# R7KA8T2AD register map
Vendor: Renesas Electronics Corporation; Series: RA8; File version: 1.10.02
CPU: CM85 r0p2, little endian, MPU, FPU, VTOR, 4 interrupt priority bits, 96 interrupts
Registers are 32-bit, read-write, reset 0x0 unless marked. A register's access mark holds for its fields unless they carry their own. Offsets are from the block's base; [hi:lo] are bit positions; {n}, {i} and the like mark numbered series; 'fields as' and 'values as' point back to an identical list.

## I3C (part 2 of 2) — I3C Bus Interface
Base 0x4035F000
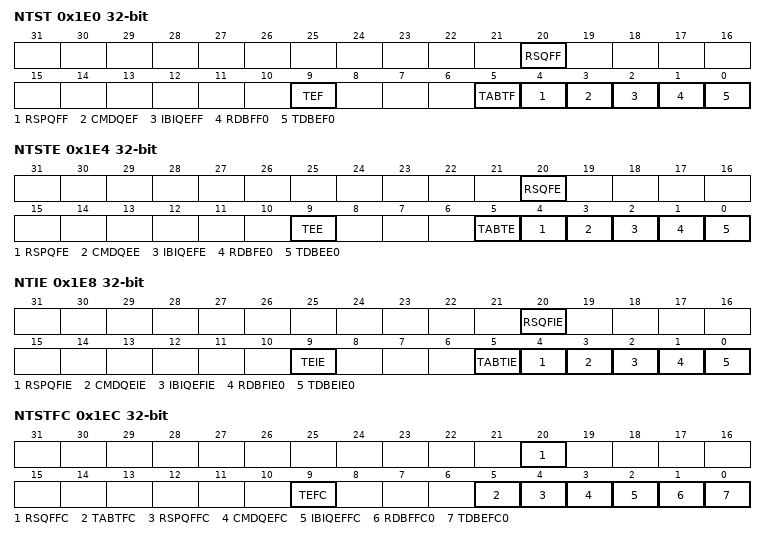
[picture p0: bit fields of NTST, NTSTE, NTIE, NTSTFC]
0x1E0 NTST — Normal Transfer Status Register
  [20] RSQFF — Normal Receive Status Queue Full Flag
    0=The number of Normal Receive Status Queue entries is the NRQTHCTL.RSQTH threshold or less; 1=The number of Normal Receive Status Queue entries is more than the NRQTHCTL.RSQTH threshold
  [9] TEF — Normal Transfer Error Flag
    0=Normal Transfer Error does not occur; 1=Normal Transfer Error occurs. To clear, write 0 to this bit after 1 state is read.
  [5] TABTF — Normal Transfer Abort Flag
    0=Normal Transfer Abort does not occur; 1=Normal Transfer Abort occur. To clear, write 0 to this bit after 1 state is read.
  [4] RSPQFF — Normal Response Queue Full Flag
    0=The number of Normal Response Queue entries is the NQTHCTL.RSPQTH threshold or less; 1=The number of Normal Response Queue entries is more than the NQTHCTL.RSPQTH threshold
  [3] CMDQEF — Normal Command Queue Empty Flag
    0=If the NQTHCTL.CMDQTH = 0: The number of Normal Command Queue empties is less than the Normal Command Queue size. If the NQTHCTL.CMDQTH is other than 0: The number of Normal Command Queue empties is less than the NQTHCTL.CMDQTH threshold.; 1=If the NQTHCTL.CMDQTH = 0: The number of Normal Command Queue empties is the Normal Command Queue size. If the NQTHCTL.CMDQTH is other than 0: 1: The number of Normal Command Queue empties is the NQTHCTL.CMDQTH threshold or more.
  [2] IBIQEFF — Normal IBI Queue Empty/Full Flag
    0=For I3C protocol mode (Master): PRTS.PRTMD bit = 0, PRSST.CRMS bit = 1. The number of Normal IBI Queue entries is the NQTHCTL.IBIQTH threshold or less. For I3C protocol mode (Slave) : PRTS.PRTMD bit = 0, PRSST.CRMS bit = 0. If the NQTHCTL.IBIQTH = 0: The number of IBI Data Buffer empties is less than the IBI Data Buffer size. If the NQTHCTL.IBIQTH is other than 0: The number of IBI Data Buffer empties is less than the NQTHCTL.IBIQTH threshold.; 1=For I3C protocol mode (Master): PRTS.PRTMD bit = 0, PRSST.CRMS bit = 1. The number of Normal IBI Queue entries is more than the NQTHCTL.IBIQTH threshold. For I3C protocol mode (Slave) : PRTS.PRTMD bit = 0, PRSST.CRMS bit = 0. If the NQTHCTL.IBIQTH = 0: The number of IBI Data Buffer empties is the IBI Data Buffer size. If the NQTHCTL.IBIQTH is other than 0: The number of IBI Data Buffer empties is the NQTHCTL.IBIQTH threshold or more.
  [1] RDBFF0 — Normal Rx Data Buffer Full Flag 0
    0=For I2C protocol mode: PRTS.PRTMD bit = 1. Normal Rx Data Buffer contains no receive data. For I3C Protocol mode: PRTS.PRTMD bit = 0. The number of entries in the Normal Rx Data Buffer is less than the NTBTHCTL0.RXDBTH[2:0] threshold.; 1=For I2C protocol mode: PRTS.PRTMD bit = 1. Normal Rx Data Buffer contains receive data. For I3C Protocol mode: PRTS.PRTMD bit = 0. The number of entries in the Normal Rx Data Buffer is the NTBTHCTL0.RXDBTH[2:0] threshold or more.
  [0] TDBEF0 — Normal Tx Data Buffer Empty Flag 0
    0=For I2C protocol mode: PRTS.PRTMD bit = 1. Normal Tx Data Buffer contains transmit data. For I3C protocol mode: PRTS.PRTMD bit = 0. The number of empties in the Normal Tx Data Buffer is less than the NTBTHCTL0.TXDBTH[2:0] threshold.; 1=For I2C protocol mode: PRTS.PRTMD bit = 1. Normal Tx Data Buffer contains no transmit data. For I3C protocol mode: PRTS.PRTMD bit = 0. The number of empties in the Normal Tx Data Buffer is the NTBTHCTL0.TXDBTH[2:0] threshold or more.
0x1E4 NTSTE — Normal Transfer Status Enable Register
  [20] RSQFE — Normal Receive Status Queue Full Enable
    0=Disables Normal Receive Status Queue Full Interrupt Status logging; 1=Enables Normal Receive Status Queue Full Interrupt Status logging
  [9] TEE — Normal Transfer Error Enable
    0=Disables Normal Transfer Error Interrupt Status logging; 1=Enables Normal Transfer Error Interrupt Status logging
  [5] TABTE — Normal Transfer Abort Enable
    0=Disables Normal Transfer Abort Interrupt Status logging; 1=Enables Normal Transfer Abort Interrupt Status logging
  [4] RSPQFE — Normal Response Queue Full Enable
    0=Disables Normal Response queue Full Interrupt Status logging; 1=Enables Normal Response queue Full Interrupt Status logging
  [3] CMDQEE — Normal Command Queue Empty Enable
    0=Disables Normal Command Queue Empty Interrupt Status logging; 1=Enables Normal Command Queue Empty Interrupt Status logging
  [2] IBIQEFE — Normal IBI Queue Empty/Full Enable
    0=Disables Normal IBI Queue Empty/Full Interrupt Status logging; 1=Enables Normal IBI Queue Empty/Full Interrupt Status logging
  [1] RDBFE0 — Normal Rx Data Buffer Full Enable 0
    0=Disables Normal Rx Data Buffer Full Interrupt Status logging; 1=Enables Normal Rx Data Buffer Full Interrupt Status logging
  [0] TDBEE0 — Normal Tx Data Buffer Empty Enable 0
    0=Disables Normal Tx Data Buffer Empty Interrupt Status logging; 1=Enables Normal Tx Data Buffer Empty Interrupt Status logging
0x1E8 NTIE — Normal Transfer Interrupt Enable Register
  [20] RSQFIE — Normal Receive Status Queue Full Interrupt Enable
    0=Disables Normal Receive Status Queue Full Interrupt Signal; 1=Enables Normal Receive Status Queue Full Interrupt Signal
  [9] TEIE — Normal Transfer Error Interrupt Enable
    0=Disables Normal Transfer Error Interrupt Signal; 1=Enables Normal Transfer Error Interrupt Signal
  [5] TABTIE — Normal Transfer Abort Interrupt Enable
    0=Disables Normal Transfer Abort Interrupt Signal; 1=Enables Normal Transfer Abort Interrupt Signal
  [4] RSPQFIE — Normal Response Queue Full Interrupt Enable
    0=Disables Normal Response Queue Full Interrupt Signal; 1=Enables Normal Response Queue Full Interrupt Signal
  [3] CMDQEIE — Normal Command Queue Empty Interrupt Enable
    0=Disables Normal Command Queue Empty Interrupt Signal; 1=Enables Normal Command Queue Empty Interrupt Signal
  [2] IBIQEFIE — Normal IBI Queue Empty/Full Interrupt Enable
    0=Disables Normal IBI Queue Empty/Full Interrupt Signal; 1=Enables Normal IBI Queue Empty/Full Interrupt Signal
  [1] RDBFIE0 — Normal Rx Data Buffer Full Interrupt Enable 0
    0=Disables Normal Rx Data Buffer Full Interrupt Signal; 1=Enables Normal Rx Data Buffer Full Interrupt Signal
  [0] TDBEIE0 — Normal Tx Data Buffer Empty Interrupt Enable 0
    0=Disables Normal Tx Data Buffer Empty Interrupt Signal; 1=Enables Normal Tx Data Buffer Empty Interrupt Signal
0x1EC NTSTFC — Normal Transfer Status Force Register
  [20] RSQFFC wo — Normal Receive Status Queue Full Force
    0=Not Force Normal Receive Status Queue Full Interrupt for software testing; 1=Force Normal Receive Status Queue Full Interrupt for software testing
  [9] TEFC wo — Normal Transfer Error Force
    0=Not Force Normal Transfer Error Interrupt for software testing; 1=Force Normal Transfer Error Interrupt for software testing
  [5] TABTFC wo — Normal Transfer Abort Force
    0=Not Force Normal Transfer Abort Interrupt for software testing; 1=Force Normal Transfer Abort Interrupt for software testing
  [4] RSPQFFC wo — Normal Response Queue Full Force
    0=Not Force Normal Response Queue Full Interrupt for software testing; 1=Force Normal Response Queue Full Interrupt for software testing
  [3] CMDQEFC wo — Normal Command Queue Empty Force
    0=Not Force Normal Command Queue Empty Interrupt for software testing; 1=Force Normal Command Queue Empty Interrupt for software testing
  [2] IBIQEFFC wo — Normal IBI Queue Empty/Full Force
    0=Not Force Normal IBI Queue Empty/Full Interrupt for software testing; 1=Force Normal IBI Queue Empty/Full Interrupt for software testing
  [1] RDBFFC0 wo — Normal Rx Data Buffer Full Force 0
    0=Not Force Normal Rx Data Buffer Full Interrupt for software testing; 1=Force Normal Rx Data Buffer Full Interrupt for software testing
  [0] TDBEFC0 wo — Normal Tx Data Buffer Empty Force 0
    0=Not Force Normal Tx Data Buffer Empty Interrupt for software testing; 1=Force Normal Tx Data Buffer Empty Interrupt for software testing
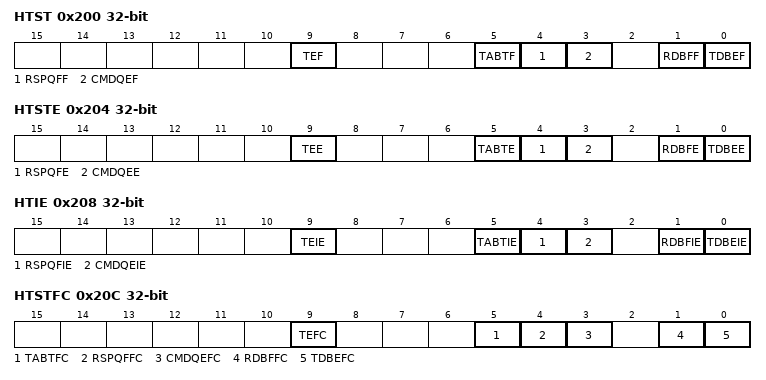
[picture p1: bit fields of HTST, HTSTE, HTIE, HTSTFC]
0x200 HTST — High Priority Transfer Status Register
  [9] TEF — High Priority Transfer Error Flag
    0=High Priority Transfer Error does not occur; 1=High Priority Transfer Error occurs. To clear, write 0 to this bit after 1 is read.
  [5] TABTF — High Priority Transfer Abort Flag
    0=High Priority Transfer Abort does not occur; 1=High Priority Transfer Abort occurs. To clear, write 0 to this bit after 1 is read.
  [4] RSPQFF — High Priority Response Queue Full Flag
    0=The number of High Priority Response Queue entries is less than the HQTHCTL .RSPQTH threshold; 1=The number of High Priority Response Queue entries is or more than the HQTHCTL .RSPQTH threshold
  [3] CMDQEF — High Priority Command Queue Empty Flag
    0=If HQTHCTL.CMDQTH is 0, the number of High Priority Command Queue empties is less than the Command Queue size. If HQTHCTL.CMDQTH is other than 0, the number of High Priority Command Queue empties is less than the HQTHCTL.CMDQTH threshold.; 1=If HQTHCTL.CMDQTH is 0, the number of High Priority Command Queue empties is the Command Queue size. If HQTHCTL.CMDQTH is other than 0, the number of High Priority Command Queue empties is or more than the HQTHCTL.CMDQTH threshold .
  [1] RDBFF — High Priority Rx Data Buffer Full Flag
    0=The number of entries in the High Priority Rx Data Buffer is less than the HTBTHCTL.RXDBTH[2:0] threshold; 1=The number of entries in the High Priority Rx Data Buffer is or more than the HTBTHCTL.RXDBTH[2:0] threshold
  [0] TDBEF — High Priority Tx Data Buffer Empty Flag
    0=The number of empties in the High Priority Tx Data Buffer is less than the HTBTHCTL.TXDBTH[2:0] threshold; 1=The number of empties in the High Priority Tx Data Buffer is or more than the HTBTHCTL.TXDBTH[2:0] threshold
0x204 HTSTE — High Priority Transfer Status Enable Register
  [9] TEE — High Priority Transfer Error Enable
    0=Disables High Priority Transfer Error interrupt Stats logging; 1=Enables High Priority Transfer Error interrupt Stats logging
  [5] TABTE — High Priority Transfer Abort Enable
    0=Disables High Priority Transfer Abort Interrupt Status logging; 1=Enables High Priority Transfer Abort Interrupt Status logging
  [4] RSPQFE — High Priority Response Queue Full Enable
    0=Disables High Priority Response Queue Full Interrupt Status logging; 1=Enables High Priority Response Queue Full Interrupt Status logging
  [3] CMDQEE — High Priority Command Queue Empty Enable
    0=Disables High Priority Command Queue Empty Interrupt Status logging; 1=Enables High Priority Command Queue Empty Interrupt Status logging
  [1] RDBFE — High Priority Rx Data Buffer Full Enable
    0=Disables High Priority Rx Data Buffer Full Interrupt Status logging; 1=Enables High Priority Rx Data Buffer Full Interrupt Status logging
  [0] TDBEE — High Priority Tx Data Buffer Empty Enable
    0=Disables High Priority Tx Data Buffer Empty Interrupt Status logging; 1=Enables High Priority Tx Data Buffer Empty Interrupt Status logging
0x208 HTIE — High Priority Transfer Interrupt Enable Register
  [9] TEIE — High Priority Transfer Error Interrupt Enable
    0=Disables High Priority Transfer Error Interrupt Signal; 1=Enables High Priority Transfer Error Interrupt Signal
  [5] TABTIE — High Priority Transfer Abort Interrupt Enable
    0=Disables High Priority Transfer Abort interrupt Signal; 1=Enables High Priority Transfer Abort interrupt Signal
  [4] RSPQFIE — High Priority Response Queue Full Interrupt Enable
    0=Disables High Priority Response Queue Full Interrupt Signal; 1=Enables High Priority Response Queue Full Interrupt Signal
  [3] CMDQEIE — High Priority Command Queue Empty Interrupt Enable
    0=Disables High Priority Command Queue Empty Interrupt Signal; 1=Enables High Priority Command Queue Empty Interrupt Signal
  [1] RDBFIE — High Priority Rx Data Buffer Full Interrupt Enable
    0=Disables High Priority Rx Data Buffer Full Interrupt Signal; 1=Enables High Priority Rx Data Buffer Full Interrupt Signal
  [0] TDBEIE — High Priority Tx Data Buffer Empty Interrupt Enable
    0=Disables High Priority Tx Data Buffer Empty Interrupt Signal; 1=Enables High Priority Tx Data Buffer Empty Interrupt Signal
0x20C HTSTFC — High Priority Transfer Status Force Register
  [9] TEFC wo — High Priority Transfer Error Force
    0=Not Force High Priority Transfer Error Interrupt for software testing; 1=Force High Priority Transfer Error Interrupt for software testing
  [5] TABTFC wo — High Priority Transfer Abort Force
    0=Not Force High Priority Transfer Abort Interrupt for software testing; 1=Force High Priority Transfer Abort Interrupt for software testing
  [4] RSPQFFC wo — High Priority Response Queue Full Force
    0=Not Force High Priority Response Queue Full Interrupt for software testing; 1=Force High Priority Response Queue Full Interrupt for software testing
  [3] CMDQEFC wo — High Priority Command Queue Empty Force
    0=Not Force High Priority Command Queue Empty Interrupt for software testing; 1=Force High Priority Command Queue Empty Interrupt for software testing
  [1] RDBFFC wo — High Priority Rx Data Buffer Full Force
    0=Not Force High Priority Rx Data Buffer Full Interrupt for software testing; 1=Force High Priority Rx Data Buffer Full Interrupt for software testing
  [0] TDBEFC wo — High Priority Tx Data Buffer Empty Force
    0=Not Force High Priority Tx Data Buffer Empty Interrupt for software testing; 1=Force High Priority Tx Data Buffer Empty Interrupt for software testing
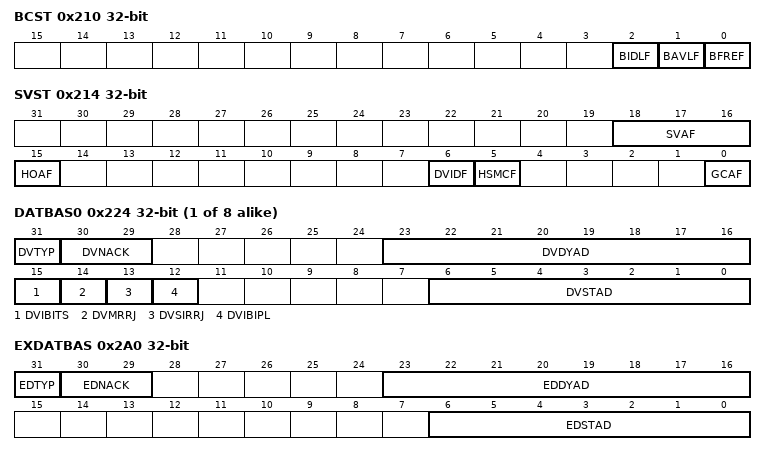
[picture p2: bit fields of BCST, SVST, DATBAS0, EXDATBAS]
0x210 BCST ro — Bus Condition Status Register
  [2] BIDLF — Bus Idle Detection Flag
    0=Have not Detected Bus Idle; 1=Have Detected Bus Idle
  [1] BAVLF — Bus Available Detection Flag
    0=Have not Detected Bus Available; 1=Have Detected Bus Available
  [0] BFREF — Bus Free Detection Flag
    0=Have not Detected Bus Free; 1=Have Detected Bus Free
0x214 SVST — Slave Status Register
  [18:16] SVAF — Slave Address Detection Flag n ( n = 0 to 2 )
    0=Slave n does not detect; 1=Slave n detect
  [15] HOAF — Host Address Detection Flag
    0=Host address does not detect; 1=Host address detects. This bit set to 1 when the received slave address matches the host address (0001 000).
  [6] DVIDF — Device-ID Address Detection Flag
    0=Device-ID command does not detect; 1=Device-ID command detects. This bit set to 1 when the first frame received immediately after a START condition is detected matches a value of (device ID (1111 100) + 0[W]).
  [5] HSMCF — Hs-mode Master Code Detection Flag
    0=Hs-mode Master Code does not detect; 1=Hs-mode Master Code detects
  [0] GCAF — General Call Address Detection Flag
    0=General call address does not detect; 1=General call address detects
0x218 WUST ro — Wake Up Unit Operating Status Register
  [0] WUASYNF — Wake-up function asynchronous operation status flag
    0=I3C synchronous circuit enable condition; 1=I3C asynchronous circuit enable condition
0x21C MRCCPT ro — MSyncCNT Counter Capture Register
{0x224+8i} DATBAS{i} (i=0..7) — Device Address Table Basic Register {i}
  [31] DVTYP — Device Type
    0=I3C Device; 1=I2C Device
  [30:29] DVNACK — Device NACK Retry Count
  [23:16] DVDYAD — Device I3C Dynamic Address
  [15] DVIBITS — Device IBI Time-stamp
    0=The Master shall not time-stamp IBIs from this Device with Master Time-stamps; 1=The Master shall time-stamp IBIs for this Device with Master Time-stamps
  [14] DVMRRJ — Device In-Band Master Request Reject
    0=This Device shall ACK Master Requests; 1=This Device shall NACK Master Requests and send the auto-disable command
  [13] DVSIRRJ — Device In-Band Slave Interrupt Request Reject
    0=This Device shall ACK the SIR; 1=This Device shall NACK the SIR and send the auto-disable CCC
  [12] DVIBIPL — Device IBI Payload
    0=IBIs from this Device do not carry a Data Payload; 1=IBIs from this Device do carry a Data Payload
  [6:0] DVSTAD — Device Static Address
0x2A0 EXDATBAS — Extended Device Address Table Basic Register
  [31] EDTYP — Extended Device Type
    0=I3C Device; 1=I2C Device
  [30:29] EDNACK — Extended Device NACK Retry Count
  [23:16] EDDYAD — Extended Device I3C Dynamic Address
  [6:0] EDSTAD — Extended Device Static Address
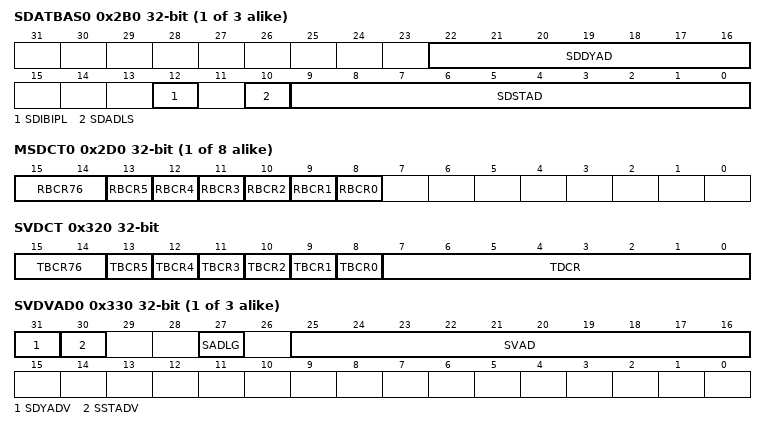
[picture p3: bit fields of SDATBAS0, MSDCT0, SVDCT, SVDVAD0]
{0x2B0+4i} SDATBAS{i} (i=0..2) — Slave Device Address Table Basic Register {i}
  [22:16] SDDYAD — Slave Device I3C Dynamic Address
  [12] SDIBIPL — Slave Device IBI Payload
    0=IBIs from this device do not carry a data payload; 1=IBIs from this device carry a data payload
  [10] SDADLS — Slave Device Address Length Selection
    0=Slave device address length 7 bits selected; 1=Slave device address length 10 bits selected. (I2C device only)
  [9:0] SDSTAD — Slave Device Static Address
{0x2D0+4i} MSDCT{i} (i=0..7) — Master Device Characteristic Table Register {i}
  [15:14] RBCR76 — Device Role
    0=I3C Slave; 1=I3C Master; other=Others (Setting prohibited)
  [13] RBCR5 — SDR Only / SDR and HDR Capable
    0=SDR only; 1=HDR Capable
  [12] RBCR4 — Bridge Identifier
    0=Not a Bridge Device; 1=A Bridge Device
  [11] RBCR3 — Offline Capable
    0=Device will always respond to I3C bus commands; 1=Device will not always respond to I3C bus commands
  [10] RBCR2 — IBI Payload
    0=No data byte follows the accepted IBI; 1=Mandatory one or more data bytes follow the accepted IBI. Data byte continuation is indicated by T-Bit.
  [9] RBCR1 — IBI Request Capable
    0=Not Capable; 1=Capable
  [8] RBCR0 — Max Data Speed Limitation
    0=No Limitation; 1=Limitation
0x320 SVDCT — Slave Device Characteristic Table Register
  [15:14] TBCR76 — Device Role
    0=I3C Slave; 1=I3C Master; other=Others (Setting prohibited)
  [13] TBCR5 — SDR Only / SDR and HDR Capable
    0=SDR only; 1=HDR Capable
  [12] TBCR4 — Bridge Identifier
    0=Not a Bridge Device; 1=A Bridge Device
  [11] TBCR3 — Offline Capable
    values as MSDCT0.RBCR3
  [10] TBCR2 — IBI Payload
    values as MSDCT0.RBCR2
  [9] TBCR1 — IBI Request Capable
    0=Not Capable; 1=Capable
  [8] TBCR0 — Max Data Speed Limitation
    0=No Limitation; 1=Limitation
  [7:0] TDCR — Transfer Device Characteristic Register
0x324 SDCTPIDL — Slave Device Characteristic Table Provisional ID Low Register
0x328 SDCTPIDH — Slave Device Characteristic Table Provisional ID High Register
{0x330+4i} SVDVAD{i} (i=0..2) ro — Slave Device Address Register {i}
  [31] SDYADV — Slave Dynamic Address Valid
    0=Dynamic Address is disabled; 1=Dynamic Address is enabled
  [30] SSTADV — Slave Static Address Valid
    0=Slave address is disabled; 1=Slave address is enabled
  [27] SADLG — Slave Address Length
    0=The 7-bit address format is selected; 1=The 10-bit address format is selected
  [25:16] SVAD — Slave Address
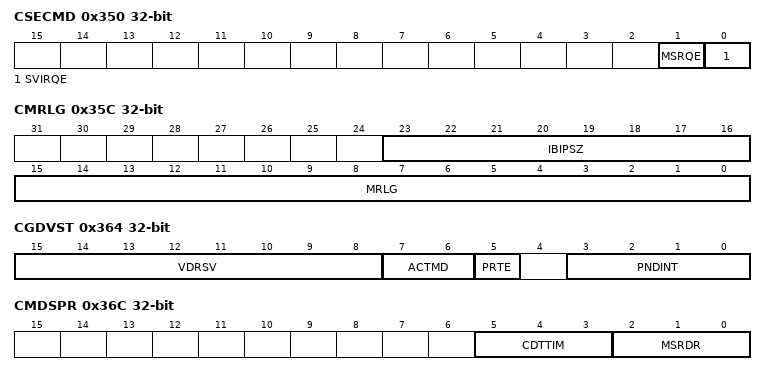
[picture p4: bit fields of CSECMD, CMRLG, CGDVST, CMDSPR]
0x350 CSECMD — CCC Slave Events Command Register
  [1] MSRQE — Mastership Requests Enable
    0=DISABLED: Mastership requests from Secondary Masters is Disabled by the Current Master to control; 1=ENABLED: Mastership requests from Secondary Masters is Enabled by the Current Master to control
  [0] SVIRQE — Slave Interrupt Requests Enable
    0=DISABLED: Slave-initiated Interrupts is Disabled by the Master to control; 1=ENABLED: Slave-initiated Interrupts is Enabled by the Master to control
0x354 CEACTST — CCC Enter Activity State Register
  [3:0] ACTST — Activity State
    1=ENTAS0 (1µs: Latency-free operation); 2=ENTAS1 (100 µs); 4=ENTAS2 (2 ms); 8=ENTAS3 (50 ms: Lowest-activity operation); other=Others (Setting prohibited)
0x358 CMWLG — CCC Max Write Length Register
  [15:0] MWLG — Max Write Length
0x35C CMRLG — CCC Max Read Length Register
  [23:16] IBIPSZ — IBI Payload Size
  [15:0] MRLG — Max Read Length
0x360 CETSTMD ro — CCC Enter Test Mode Register
  [7:0] TSTMD — Test Mode
    0=Exit Test Mode This value removes all I3C devices from Test Mode; 1=Vendor Test Mode This value indicates that I3C devices shall return a random 32bit value in the provisional ID during the Dynamic Address Assignment procedure; other=Others (Setting prohibited)
0x364 CGDVST — CCC Get Device Status Register
  [15:8] VDRSV — Vendor Reserved
  [7:6] ACTMD — Slave Device’s current Activity Mode
    {v}=Activity Mode {v} (v=0..3)
  [5] PRTE — Protocol Error
    0=The Slave has not detected a protocol error since the last Status read; 1=The Slave has detected a protocol error since the last Status read
  [3:0] PNDINT — Pending Interrupt
0x368 CMDSPW — CCC Max Data Speed W (Write) Register
  [2:0] MSWDR — Maximum Sustained Write Data Rate
    0=fscl Max (default value); 1=8 MHz; 2=6 MHz; 3=4 MHz; 4=2 MHz; other=Others (Setting prohibited)
0x36C CMDSPR — CCC Max Data Speed R (Read) Register
  [5:3] CDTTIM — Clock to Data Turnaround Time (TSCO)
    0=8 ns or less (default value); {v}={v+8} ns or less (v=1..4); 7=TSCO is more than 12 ns, and is reported by private agreement; other=Others (Setting prohibited)
  [2:0] MSRDR — Maximum Sustained Read Data Rate
    values as CMDSPW.MSWDR
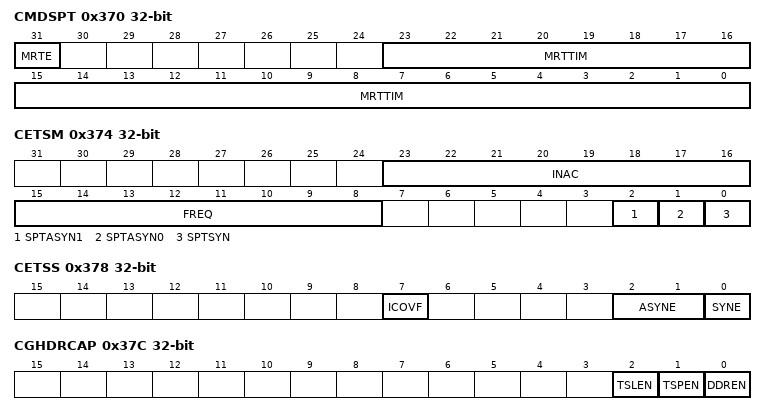
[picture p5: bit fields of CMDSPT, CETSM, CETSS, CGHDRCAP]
0x370 CMDSPT — CCC Max Data Speed T (Turnaround) Register
  [31] MRTE — Maximum Read Turnaround Time Enable
    0=Disables transmission of the Maximum Read Turnaround Time. (GETMXDS Format 1: Without Turnaround); 1=Enables transmission of the Maximum Read Turnaround Time. (GETMXDS Format 2: With Turnaround)
  [23:0] MRTTIM — Maximum Read Turnaround Time
0x374 CETSM — CCC Exchange Timing Support Information M (Mode) Register
  [23:16] INAC — Inaccuracy Byte
  [15:8] FREQ — Frequency Byte
  [2] SPTASYN1 — Support Async Mode 1
    0=Async Mode 1 is not supported; 1=Async Mode 1 is supported
  [1] SPTASYN0 — Support Async Mode 0
    0=Async Mode 0 is not supported; 1=Async Mode 0 is supported
  [0] SPTSYN — Supports Sync Mode
    0=Sync Mode is not supported; 1=Sync Mode is supported
0x378 CETSS — CCC Exchange Timing Support Information S (State) Register
  [7] ICOVF — Internal Counter Overflow
    0=Slave has not experienced a counter overflow since the most recent previous check; 1=Slave experienced a counter overflow since the most recent previous check
  [2:1] ASYNE — Async Mode Enabled
    0=All Mode Disable; 1=Async Mode 0 Enabled; 2=Async Mode 1 Enabled; other=Others (Setting prohibited)
  [0] SYNE — Sync Mode Enabled
    0=Sync Mode Disabled; 1=Sync Mode Enabled
0x37C CGHDRCAP — CCC Get HDR Capability Register
  [2] TSLEN — HDR-TSL Operation Enable
    0=HDR-TSL Operation is Disabled; 1=HDR-TSL Operation is Enabled
  [1] TSPEN — HDR-TSP Operation Enable
    0=HDR-TSP Operation is Disabled; 1=HDR-TSP Operation is Enabled
  [0] DDREN — HDR-DDR Operation Enable
    0=HDR-DDR Operation is Disabled; 1=HDR-DDR Operation is Enabled
0x380 BITCNT ro — Bit Count Register
  [4:0] BCNT — Bit Counter
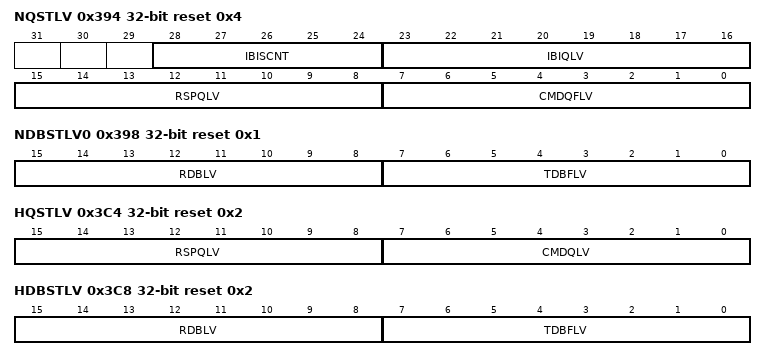
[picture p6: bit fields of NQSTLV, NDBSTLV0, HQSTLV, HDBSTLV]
0x394 NQSTLV ro reset 0x4 — Normal Queue Status Level Register
  [28:24] IBISCNT — Normal IBI Status Count
  [23:16] IBIQLV — Normal IBI Queue Level
  [15:8] RSPQLV — Normal Response Queue Level
  [7:0] CMDQFLV — Normal Command Queue Free Level
0x398 NDBSTLV0 ro reset 0x1 — Normal Data Buffer Status Level Register 0
  [15:8] RDBLV — Normal Rx Data Buffer Level
  [7:0] TDBFLV — Normal Tx Data Buffer Free Level
0x3C0 NRSQSTLV ro — Normal Receive Status Queue Status Level Register
  [7:0] RSQLV — Normal Receive Status Queue Level
0x3C4 HQSTLV ro reset 0x2 — High Priority Queue Status Level Register
  [15:8] RSPQLV — High Priority Response Queue Level
  [7:0] CMDQLV — High Priority Command Queue Level
0x3C8 HDBSTLV ro reset 0x2 — High Priority Data Buffer Status Level Register
  [15:8] RDBLV — High Priority Rx Data Buffer Level
  [7:0] TDBFLV — High Priority Tx Data Buffer Free Level
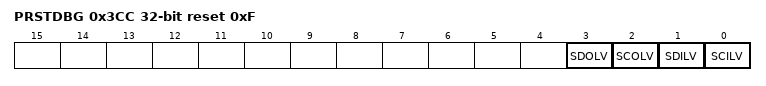
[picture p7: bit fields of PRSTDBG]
0x3CC PRSTDBG ro reset 0xF — Present State Debug Register
  [3] SDOLV — SDA Output Level
    0=I3C has driven the I3C_SDA pin low; 1=I3C has released the I3C_SDA pin
  [2] SCOLV — SCL Output Level
    0=I3C has driven the I3C_SCL pin low; 1=I3C has released the I3C_SCL pin
  [1] SDILV — I3C_SDA Line Signal Level
  [0] SCILV — I3C_SCL Line Signal Level
0x3D0 MSERRCNT ro — Master Error Counters Register
  [7:0] M2ECNT — M2 Error Counter
0x3E0 SC1CPT ro — SC1 Capture Monitor Register
  [15:0] SC1C — SC1 Capture
0x3E4 SC2CPT ro — SC2 Capture Monitor Register
  [15:0] SC2C — SC2 Capture

## I3C_NS (part 2 of 2) — I3C Bus Interface
Base 0x5035F000
Registers as I3C; these are added or differ:
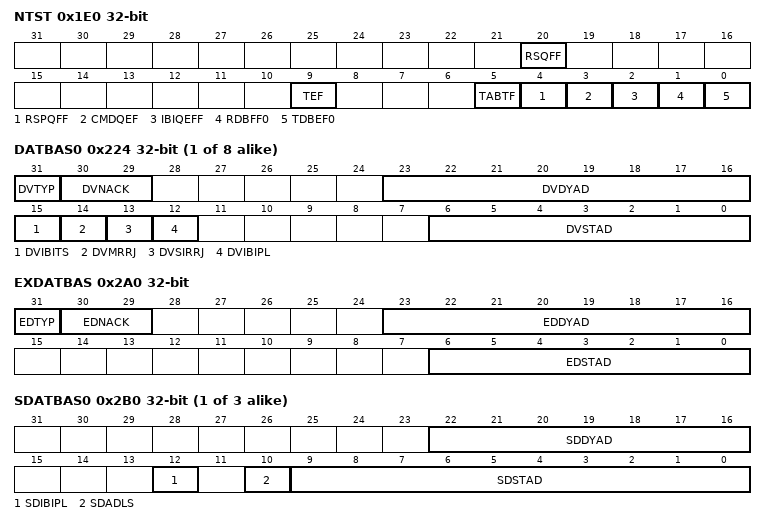
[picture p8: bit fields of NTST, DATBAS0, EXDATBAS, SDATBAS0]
0x1E0 NTST — Normal Transfer Status Register
  fields as I3C.NTST
0x218 WUST ro — Wake Up Unit Operating Status Register
  [0] WUASYNF — Wake-up function asynchronous operation status flag
    0=I3C synchronous circuit enable condition; 1=I3C asynchronous circuit enable condition
{0x224+8i} DATBAS{i} (i=0..7) — Device Address Table Basic Register {i}
  fields as I3C.DATBAS0
0x2A0 EXDATBAS — Extended Device Address Table Basic Register
  fields as I3C.EXDATBAS
{0x2B0+4i} SDATBAS{i} (i=0..2) — Slave Device Address Table Basic Register {i}
  fields as I3C.SDATBAS0
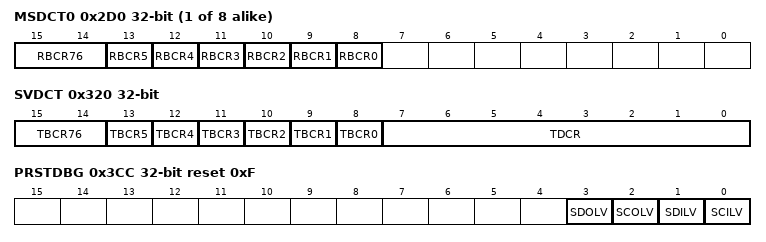
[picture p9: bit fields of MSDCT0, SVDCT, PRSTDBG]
{0x2D0+4i} MSDCT{i} (i=0..7) — Master Device Characteristic Table Register {i}
  fields as I3C.MSDCT0
0x320 SVDCT — Slave Device Characteristic Table Register
  fields as I3C.SVDCT
0x360 CETSTMD ro — CCC Enter Test Mode Register
  fields as I3C.CETSTMD
0x3CC PRSTDBG ro reset 0xF — Present State Debug Register
  fields as I3C.PRSTDBG
